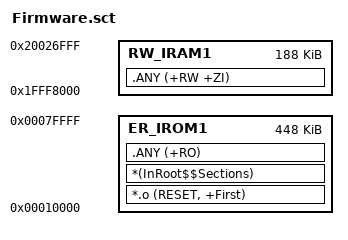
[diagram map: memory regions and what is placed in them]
; *************************************************************
; *** Scatter-Loading Description File generated by uVision ***
; *************************************************************
; App @ 0x10000 (64KB boot 之后, 与 F4A0 布局一致)
;   0x00000-0x0FFFF: bootloader (64KB)
;   0x10000-0x7FFFF: App (448KB)

LR_IROM1 0x00010000 0x00070000  {    ; load region size_region
  ER_IROM1 0x00010000 0x00070000  {  ; load address = execution address
   *.o (RESET, +First)
   *(InRoot$$Sections)
   .ANY (+RO)
  }
  RW_IRAM1 0x1FFF8000 0x0002F000  {  ; RW data
   .ANY (+RW +ZI)
  }
}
